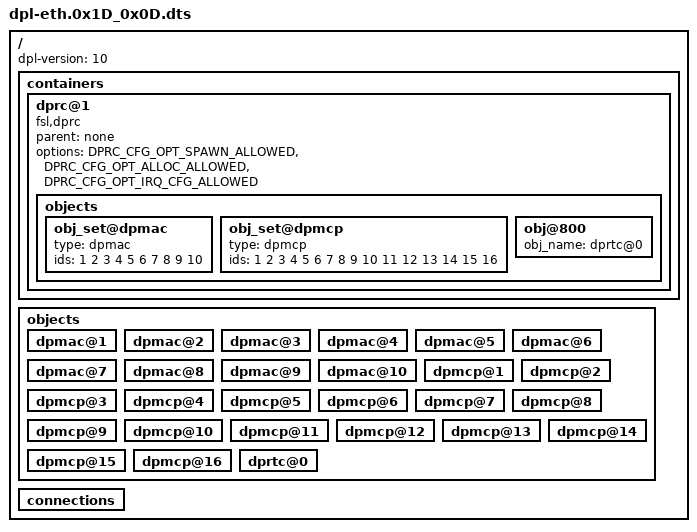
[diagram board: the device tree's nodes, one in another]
/*
 * Copyright 2016 Freescale Semiconductor, Inc.
 * "Bootstrap DPL" for ls1088a featuring SerDes 0x1D_0x0D.
 * This together with the available DPMCP objects should be enough to boot Linux
 * and to allow the dynamic addition of other objects to the Linux container,
 * using the 'restool' utility.
 */

/dts-v1/;
/ {
	dpl-version = <10>;
	/*****************************************************************
	 * Containers
	 *****************************************************************/
	containers {
		dprc@1 {
			compatible = "fsl,dprc";
			parent = "none";
			options = "DPRC_CFG_OPT_SPAWN_ALLOWED" , "DPRC_CFG_OPT_ALLOC_ALLOWED", "DPRC_CFG_OPT_IRQ_CFG_ALLOWED";
			objects {
				/* ------------- MACs --------------*/
				obj_set@dpmac {
					type = "dpmac";
					ids = <1 2 3 4 5 6 7 8 9 10>;
				};

				/* ------------ DPMCPs --------------*/
				obj_set@dpmcp {
					type = "dpmcp";
					ids = <1 2 3 4 5 6 7 8 9 10 11 12 13 14 15 16>;
				};

				/* ------------ DPRTC --------------*/
				obj@800 {
					obj_name="dprtc@0";
				};
			};
		};
	};

	/*****************************************************************
	 * Objects
	 *****************************************************************/
	objects {
		/* ------------ DPMAC --------------*/
		dpmac@1 {
		};
		dpmac@2 {
		};
		dpmac@3 {
		};
		dpmac@4 {
		};
		dpmac@5 {
		};
		dpmac@6 {
		};
		dpmac@7 {
		};
		dpmac@8 {
		};
		dpmac@9 {
		};
		dpmac@10 {
		};

		/* ------------ DPMCP --------------*/
		dpmcp@1 {
		};
		dpmcp@2 {
		};
		dpmcp@3 {
		};
		dpmcp@4 {
		};
		dpmcp@5 {
		};
		dpmcp@6 {
		};
		dpmcp@7 {
		};
		dpmcp@8 {
		};
		dpmcp@9 {
		};
		dpmcp@10 {
		};
		dpmcp@11 {
		};
		dpmcp@12 {
		};
		dpmcp@13 {
		};
		dpmcp@14 {
		};
		dpmcp@15 {
		};
		dpmcp@16 {
		};

		/* ------------ DPRTC --------------*/
		dprtc@0 {
		};
	};

	/*****************************************************************
	 * Connections
	 *****************************************************************/
	connections {
	};
};
